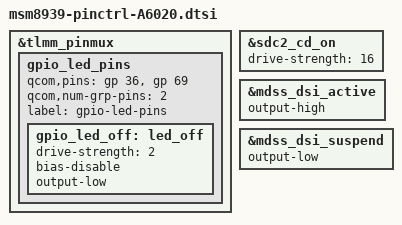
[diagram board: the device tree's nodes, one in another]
/* Copyright (c) 2014-2015, The Linux Foundation. All rights reserved.
 *
 * This program is free software; you can redistribute it and/or modify
 * it under the terms of the GNU General Public License version 2 and
 * only version 2 as published by the Free Software Foundation.
 *
 * This program is distributed in the hope that it will be useful,
 * but WITHOUT ANY WARRANTY; without even the implied warranty of
 * MERCHANTABILITY or FITNESS FOR A PARTICULAR PURPOSE.  See the
 * GNU General Public License for more details.
 */


&tlmm_pinmux {
	gpio_led_pins {
		qcom,pins = <&gp 36>,<&gp 69>;
		qcom,num-grp-pins = <2>;
		label = "gpio-led-pins";
		gpio_led_off: led_off {
			drive-strength = <2>;
			bias-disable;
			output-low;
		};
	};
};

&sdc2_cd_on{
	drive-strength = <16>;
};

&mdss_dsi_active {
	output-high;
};

&mdss_dsi_suspend {
	output-low;
};


